VERSION ""

NS_ :

BS_:

BU_: Computer PDU_HIL VCU_HIL

BO_ 2281836306 PDU_message_status: 1 PDU_HIL
 SG_ Batt_thermistor_status : 0|1@1+ (1,0) [0|1] ""  Computer

BO_ 2214662671 Batt_thermistor: 3 Computer
 SG_ Batt_thermistor : 0|18@1+ (1,0) [60|200060] "Ohm"  PDU_HIL

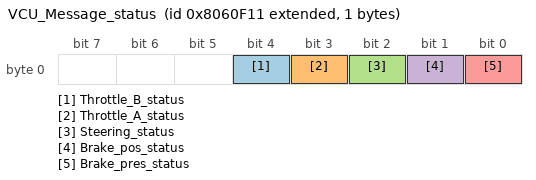
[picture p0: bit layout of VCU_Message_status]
BO_ 2282098449 VCU_Message_status: 1 VCU_HIL
 SG_ Throttle_B_status : 4|1@1+ (1,0) [0|1] ""  Computer
 SG_ Throttle_A_status : 3|1@1+ (1,0) [0|1] ""  Computer
 SG_ Steering_status : 2|1@1+ (1,0) [0|1] ""  Computer
 SG_ Brake_pos_status : 1|1@1+ (1,0) [0|1] ""  Computer
 SG_ Brake_pres_status : 0|1@1+ (1,0) [0|1] ""  Computer

BO_ 2214924559 Steering_raw: 2 Computer
 SG_ Steering_raw : 0|12@1+ (1,0) [0|3300] "mV"  VCU_HIL

BO_ 2214859023 Brake_position: 2 Computer
 SG_ Brake_position : 0|12@1+ (1,0) [0|3300] "mV"  VCU_HIL

BO_ 2214793487 Brake_pres_raw: 2 Computer
 SG_ Brake_pres_raw : 0|12@1+ (1,0) [0|3300] "mV"  VCU_HIL

BO_ 2214727951 Throttle_position_B: 2 Computer
 SG_ Throttle_position_B : 0|12@1+ (1,0) [0|3300] "mV"  VCU_HIL

BO_ 2214662415 Throttle_position_A: 2 Computer
 SG_ Throttle_position_A : 0|12@1+ (1,0) [0|3300] "mV"  VCU_HIL

CM_ SG_ 2214662415 Throttle_position_A "
";
BA_DEF_  "BusType" STRING ;
BA_DEF_DEF_  "BusType" "CAN";
